# STM32MP153 register map
File version: 1.3
CPU: CM4 r0p1, little endian, no MPU, FPU, 4 interrupt priority bits
Registers are 32-bit, read-write, reset 0x0 unless marked. A register's access mark holds for its fields unless they carry their own. Offsets are from the block's base; [hi:lo] are bit positions; {n}, {i} and the like mark numbered series; 'fields as' and 'values as' point back to an identical list.

## FMC — FMC register block
Base 0x58002000
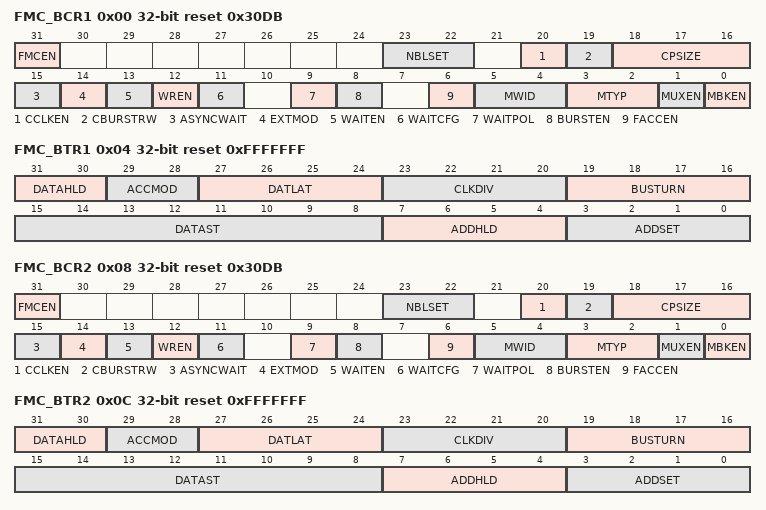
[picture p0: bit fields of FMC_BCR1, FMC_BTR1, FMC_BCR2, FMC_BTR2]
0x00 FMC_BCR1 reset 0x30DB — This register contains the control information of each memory bank, used for SRAMs, PSRAM, FRAM and NOR Flash memories.
  [31] FMCEN, [23:22] NBLSET, [20] CCLKEN, [19] CBURSTRW, [18:16] CPSIZE, [15] ASYNCWAIT, [14] EXTMOD, [13] WAITEN, [12] WREN, [11] WAITCFG, [9] WAITPOL, [8] BURSTEN, [6] FACCEN, [5:4] MWID, [3:2] MTYP, [1] MUXEN, [0] MBKEN
0x04 FMC_BTR1 reset 0xFFFFFFF — This register contains the control information of each memory bank, used for SRAMs, PSRAM and NOR Flash memories.If the EXTMOD bit is set in the FMC_BCRx register, then this register is partitioned for write and read access, that is, two registers are available: one to configure read accesses (this register) and one to configure write accesses (FMC_BWTRx registers).
  [31:30] DATAHLD, [29:28] ACCMOD, [27:24] DATLAT, [23:20] CLKDIV, [19:16] BUSTURN, [15:8] DATAST, [7:4] ADDHLD, [3:0] ADDSET
0x08 FMC_BCR2 reset 0x30DB — This register contains the control information of each memory bank, used for SRAMs, PSRAM, FRAM and NOR Flash memories.
  fields as FMC_BCR1
0x0C FMC_BTR2 reset 0xFFFFFFF — This register contains the control information of each memory bank, used for SRAMs, PSRAM and NOR Flash memories.If the EXTMOD bit is set in the FMC_BCRx register, then this register is partitioned for write and read access, that is, two registers are available: one to configure read accesses (this register) and one to configure write accesses (FMC_BWTRx registers).
  fields as FMC_BTR1
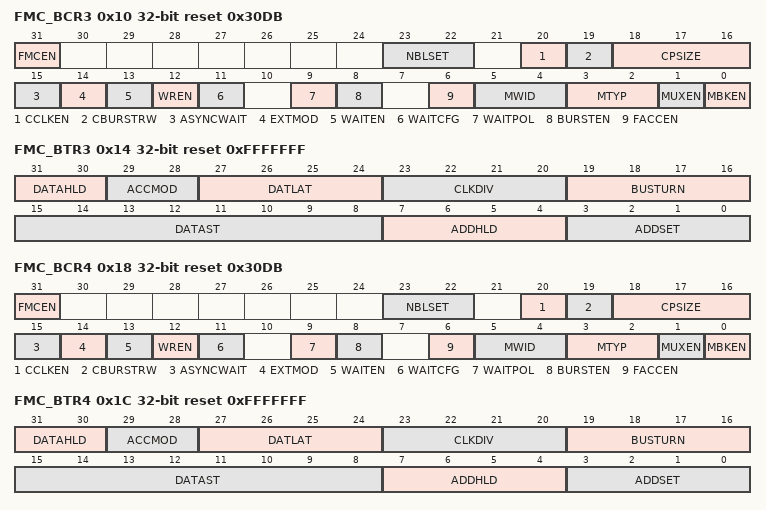
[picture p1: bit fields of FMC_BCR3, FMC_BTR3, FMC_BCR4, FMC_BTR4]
0x10 FMC_BCR3 reset 0x30DB — This register contains the control information of each memory bank, used for SRAMs, PSRAM, FRAM and NOR Flash memories.
  fields as FMC_BCR1
0x14 FMC_BTR3 reset 0xFFFFFFF — This register contains the control information of each memory bank, used for SRAMs, PSRAM and NOR Flash memories.If the EXTMOD bit is set in the FMC_BCRx register, then this register is partitioned for write and read access, that is, two registers are available: one to configure read accesses (this register) and one to configure write accesses (FMC_BWTRx registers).
  fields as FMC_BTR1
0x18 FMC_BCR4 reset 0x30DB — This register contains the control information of each memory bank, used for SRAMs, PSRAM, FRAM and NOR Flash memories.
  fields as FMC_BCR1
0x1C FMC_BTR4 reset 0xFFFFFFF — This register contains the control information of each memory bank, used for SRAMs, PSRAM and NOR Flash memories.If the EXTMOD bit is set in the FMC_BCRx register, then this register is partitioned for write and read access, that is, two registers are available: one to configure read accesses (this register) and one to configure write accesses (FMC_BWTRx registers).
  fields as FMC_BTR1
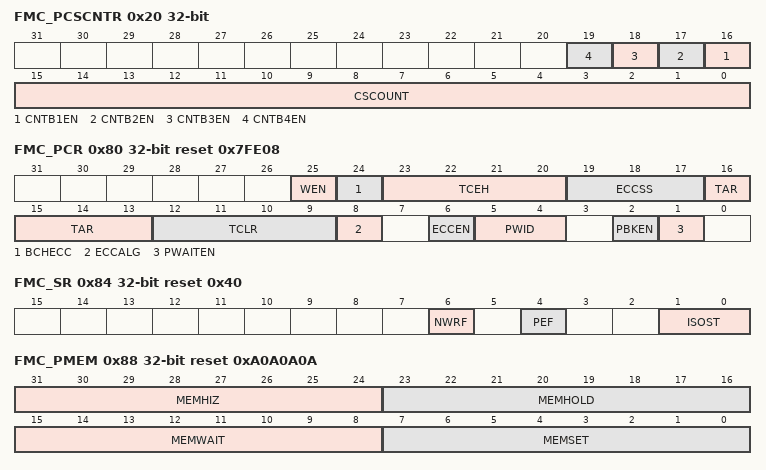
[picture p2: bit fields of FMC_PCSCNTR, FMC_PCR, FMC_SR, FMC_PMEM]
0x20 FMC_PCSCNTR — This register contains the PSRAM chip select counter value for synchronous mode. The chip select counter is common to all banks and can be enabled separately on each bank. During PSRAM read or write accesses, this value is loaded into a timer which is decremented using the fmc_ker_ck while the NE signal is held low. When the timer reaches 0, the PSRAM controller splits the current access, toggles NE to allow PSRAM device refresh and restarts a new access. The programmed counter value guarantees a maximum NE pulse width (tCEM) as specified for PSRAM devices. The counter is reloaded and starts decrementing each time a new access is started by a transition of NE from high to low. h
  [n+15] CNTB{n}EN (n=1..4), [15:0] CSCOUNT
0x80 FMC_PCR reset 0x7FE08 — NAND Flash Programmable control register
  [25] WEN, [24] BCHECC, [23:20] TCEH, [19:17] ECCSS, [16:13] TAR, [12:9] TCLR, [8] ECCALG, [6] ECCEN, [5:4] PWID, [2] PBKEN, [1] PWAITEN
0x84 FMC_SR ro reset 0x40 — This register contains information about the AXI interface isolation status and the NAND write requests status. The FMC has to be disabled before modifying some registers. As requests might be pending, it is necessary to wait till the AXI interface is stable and the core of the block is totally isolated from its AXI interface before reconfiguring the registers. The PEF and PNWEF bits indicate the status of the pipe. If Hamming algorithm is used, the ECC is calculated while data are written to the memory. To read the correct ECC, the software must consequently wait untill no write request to the NAND controller are pending, by polling PEF and NWRF bits.
  [6] NWRF, [4] PEF, [1:0] ISOST
0x88 FMC_PMEM reset 0xA0A0A0A — The FMC_PMEM read/write register contains NAND Flash memory bank timing information. This information is used to access the NAND Flash common memory space for command, address write accesses or data read/write accesses.
  [31:24] MEMHIZ, [23:16] MEMHOLD, [15:8] MEMWAIT, [7:0] MEMSET
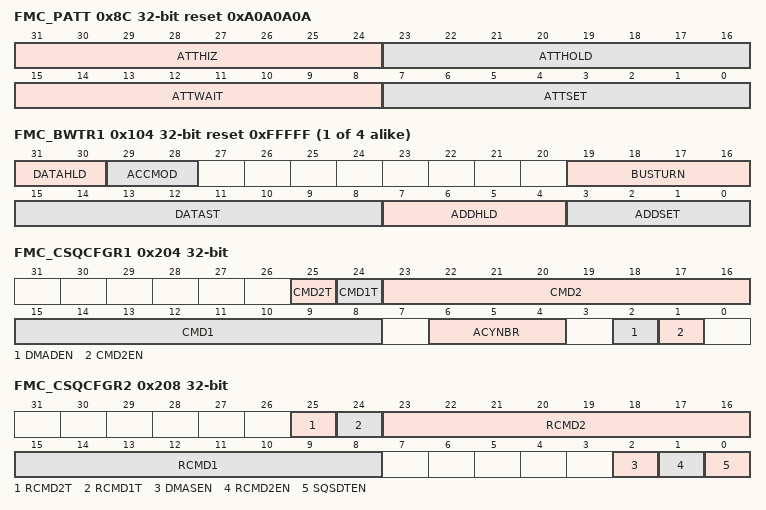
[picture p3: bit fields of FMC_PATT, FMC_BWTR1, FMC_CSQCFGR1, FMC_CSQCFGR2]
0x8C FMC_PATT reset 0xA0A0A0A — The FMC_PATT read/write register contains NAND Flash memory bank timing information. It is used for 8-bit accesses to the NAND Flash attribute memory space during the last address write access when the timing differs from previous accesses (for Ready/Busy management, refer to Section25.8.5: NAND Flash prewait function).
  [31:24] ATTHIZ, [23:16] ATTHOLD, [15:8] ATTWAIT, [7:0] ATTSET
0x90 FMC_HPR ro — This register is used during read accesses in conjunction with the FMC sequencer. It contains the current error correction code value computed by the FMC NAND controller Hamming module. When the FMC sequencer reads data from a NAND Flash memory page at the correct address, the data read are automatically processed by the Hamming computation module. When X bytes have been read (according to the sector size ECCSS field in the FMC_PCR register), the CPU must read the computed ECC value from the FMC_HECCR register. It then verifies if these computed parity data are the same as the parity value recorded in the spare area and stored in the and the FMC_HPR, to determine whether a page is valid, and to correct it otherwise. The FMC_HPR register should be cleared after being read by setting the ECCEN bit to 0. To compute a new data block, the ECCEN bit must be set to 1.
0x94 FMC_HECCR ro — This register contain the current error correction code value computed by the FMC NAND controller Hamming module.When the CPU reads/writes data from/to a NAND Flash memory page at the correct address (refer to Section25.8.6: NAND ECC controller), the data read/written from/to the NAND Flash memory are automatically processed by the Hamming computation module. When X bytes have been read (according to the sector size ECCSS field in the FMC_PCR register), the CPU must read the computed ECC value from the FMC_HECCR register. It then verifies if these computed parity data are the same as the parity value recorded in the spare area, to determine whether a page is valid, and to correct it otherwise. The FMC_HECCR register should be cleared after being read by setting the ECCEN bit to 0. To compute a new data block, the ECCEN bit must be set to 1.
  [31:0] HECC
{0xFC+8i} FMC_BWTR{i} reset 0xFFFFF (i=1..4) — This register contains the control information of each memory bank. It is used for SRAMs, FRAMs, PSRAMs and NOR Flash memories. When the EXTMOD bit is set in the FMC_BCRx register, then this register is active for write access.
  [31:30] DATAHLD, [29:28] ACCMOD, [19:16] BUSTURN, [15:8] DATAST, [7:4] ADDHLD, [3:0] ADDSET
0x200 FMC_CSQCR wo — FMC NAND Command Sequencer Control Register
  [0] CSQSTART
0x204 FMC_CSQCFGR1 — FMC NAND Command Sequencer Configuration Register 1
  [25] CMD2T, [24] CMD1T, [23:16] CMD2, [15:8] CMD1, [6:4] ACYNBR, [2] DMADEN, [1] CMD2EN
0x208 FMC_CSQCFGR2 — This register is used to configure the command sequencer to issue random read/ write commands to read/ write data by sector and automatically read/write data from NAND Flash memory at a programmable address offset. This is useful when performing a sector read/write operation followed by an ECC read/write operation in the NAND Flash spare area.The command sequencer generates the random commands untill all the sectors are read/written. .
  [25] RCMD2T, [24] RCMD1T, [23:16] RCMD2, [15:8] RCMD1, [2] DMASEN, [1] RCMD2EN, [0] SQSDTEN
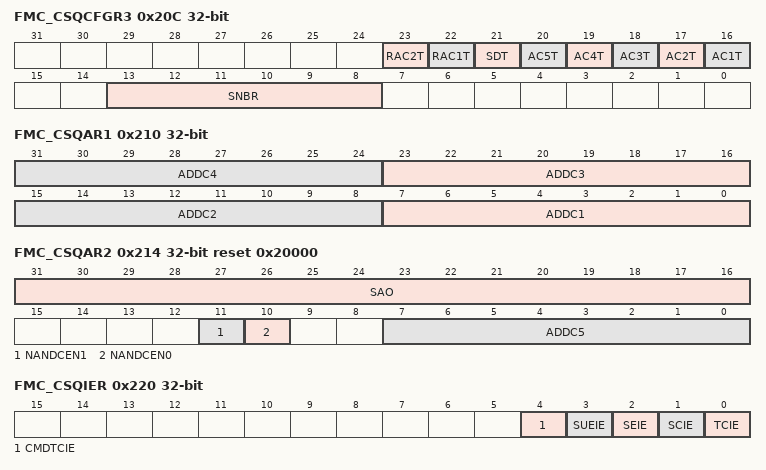
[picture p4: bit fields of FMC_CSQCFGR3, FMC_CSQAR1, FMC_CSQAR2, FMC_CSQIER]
0x20C FMC_CSQCFGR3 — FMC NAND sequencer configuration register 3
  [23] RAC2T, [22] RAC1T, [21] SDT, [n+15] AC{n}T (n=1..5), [13:8] SNBR
0x210 FMC_CSQAR1 — This register is used to define the value of address cycles 1 to 4 to be issued by the command sequencer.
  [8n-1:8n-8] ADDC{n} (n=1..4)
0x214 FMC_CSQAR2 reset 0x20000 — This register is used to program the fifth address cycle and the address offset in spare area. It also selects the chip enable.
  [31:16] SAO, [11] NANDCEN1, [10] NANDCEN0, [7:0] ADDC5
0x220 FMC_CSQIER — FMC NAND Command Sequencer Interrupt Enable Register
  [4] CMDTCIE, [3] SUEIE, [2] SEIE, [1] SCIE, [0] TCIE
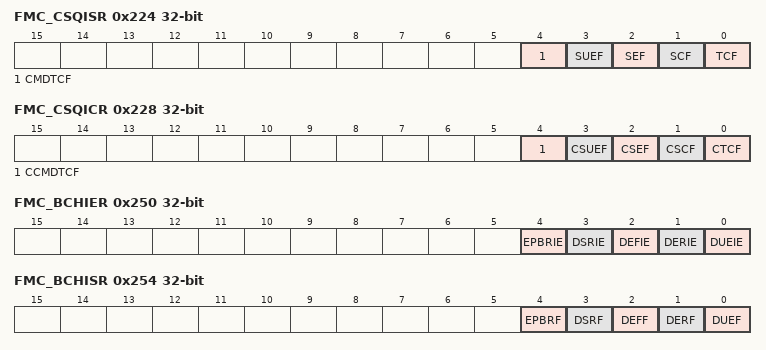
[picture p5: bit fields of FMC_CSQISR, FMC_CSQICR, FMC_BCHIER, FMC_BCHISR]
0x224 FMC_CSQISR — FMC NAND Command Sequencer Interrupt Status Register
  [4] CMDTCF, [3] SUEF, [2] SEF, [1] SCF, [0] TCF
0x228 FMC_CSQICR wo — FMC NAND Command Sequencer Interrupt Clear Register
  [4] CCMDTCF, [3] CSUEF, [2] CSEF, [1] CSCF, [0] CTCF
0x230 FMC_CSQEMSR ro — This register holds a sector error mapping status when the whole transfer is complete.
  [15:0] SEM
0x250 FMC_BCHIER — FMC BCH Interrupt enable register
  [4] EPBRIE, [3] DSRIE, [2] DEFIE, [1] DERIE, [0] DUEIE
0x254 FMC_BCHISR ro — This register holds the status of BCH encoder/decoder after processing each sector. When the sequencer is used, this register is automatically cleared.
  [4] EPBRF, [3] DSRF, [2] DEFF, [1] DERF, [0] DUEF
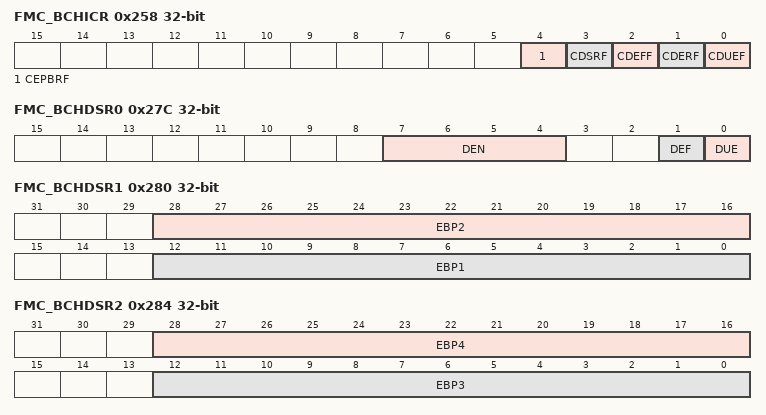
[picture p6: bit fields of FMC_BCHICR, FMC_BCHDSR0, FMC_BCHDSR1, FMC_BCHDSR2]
0x258 FMC_BCHICR wo — FMC BCH Interrupt Clear Register
  [4] CEPBRF, [3] CDSRF, [2] CDEFF, [1] CDERF, [0] CDUEF
0x260 FMC_BCHPBR1 ro — These registers contain the BCH parity bits (BCHPB). For the BCH 4-bit, only BCHPB[51:0] are significant and for the BCH 8-bit BCHPB[103:0] are significant.
  [31:0] BCHPB
0x264 FMC_BCHPBR2 ro — FMC BCH Parity Bits Register 2
  [31:0] BCHPB
0x268 FMC_BCHPBR3 ro — FMC BCH Parity Bits Register 3
  [31:0] BCHPB
0x26C FMC_BCHPBR4 ro — FMC BCH Parity Bits Register 4
  [7:0] BCHPB
0x27C FMC_BCHDSR0 ro — This register contains some fields already available in other registers but that require to be saved when error correction is performed on several sectors at a time (for example a whole NAND Flash page). This allows a DMA channel to transfer the content of FMC_BCHDSR0..4 to a decoding status buffer. .
  [7:4] DEN, [1] DEF, [0] DUE
0x280 FMC_BCHDSR1 ro — The maximum error correction capability of the BCH block embedded in the FMC is 8 errors
  [28:16] EBP2, [12:0] EBP1
0x284 FMC_BCHDSR2 ro — The maximum error correction capability of the BCH block embedded in the FMC is 8 errors. This register contains the positions of the 3rd and 4th error bits in EBP3 and EPB4 fields, respectively.
  [28:16] EBP4, [12:0] EBP3
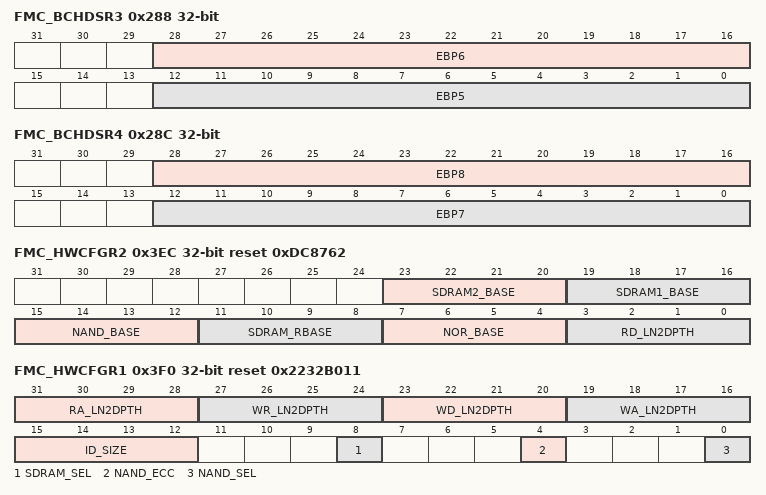
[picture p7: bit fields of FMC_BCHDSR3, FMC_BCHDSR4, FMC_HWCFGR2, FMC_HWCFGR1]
0x288 FMC_BCHDSR3 ro — The maximum error correction capability of the BCH block embedded in the FMC is 8 errors.
  [28:16] EBP6, [12:0] EBP5
0x28C FMC_BCHDSR4 ro — The maximum error correction capability of the BCH block embedded in the FMC is 8 errors. This register contains the positions of the 7th and 8th error bits in EBP7 and EPB8 fields, respectively. .
  [28:16] EBP8, [12:0] EBP7
0x3EC FMC_HWCFGR2 ro reset 0xDC8762 — FMC Hardware configuration register 2
  [23:20] SDRAM2_BASE, [19:16] SDRAM1_BASE, [15:12] NAND_BASE, [11:8] SDRAM_RBASE, [7:4] NOR_BASE, [3:0] RD_LN2DPTH
0x3F0 FMC_HWCFGR1 ro reset 0x2232B011 — FMC Hardware configuration register 1
  [31:28] RA_LN2DPTH, [27:24] WR_LN2DPTH, [23:20] WD_LN2DPTH, [19:16] WA_LN2DPTH, [15:12] ID_SIZE, [8] SDRAM_SEL, [4] NAND_ECC, [0] NAND_SEL
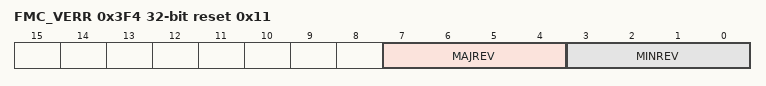
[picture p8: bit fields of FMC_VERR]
0x3F4 FMC_VERR ro reset 0x11 — FMC Version register
  [7:4] MAJREV, [3:0] MINREV
0x3F8 FMC_IPIDR ro reset 0x140001 — FMC Identification register
  [31:0] ID
0x3FC FMC_SIDR ro reset 0xA3C5DD01 — FMC Size Identification register
  [31:0] SID
